# APM32F446 register map
File version: 1.0
CPU: CM4 r0p1, little endian, MPU, FPU, 4 interrupt priority bits
Registers are 32-bit, read-write, reset 0x0 unless marked. A register's access mark holds for its fields unless they carry their own. Offsets are from the block's base; [hi:lo] are bit positions; {n}, {i} and the like mark numbered series.

## LPSPI0 — The LPSPI Memory Map/Register Definition can be found here.
Base 0x4002C000
Same registers: LPSPI1 0x4002D000, LPSPI2 0x4002E000
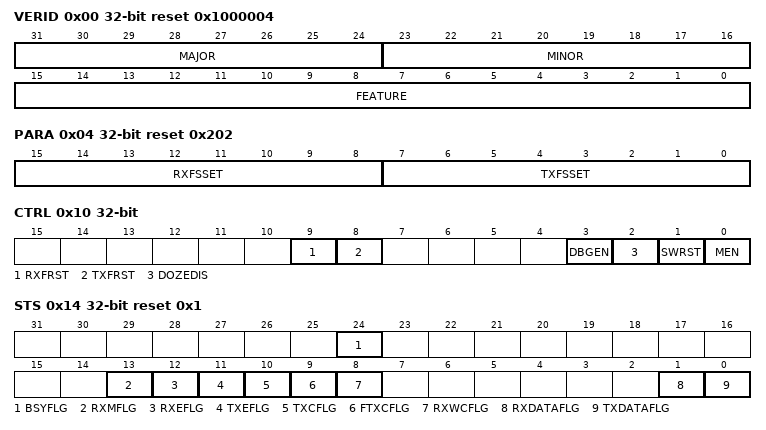
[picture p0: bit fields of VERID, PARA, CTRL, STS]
0x00 VERID ro reset 0x1000004 — Version ID Register
  [31:24] MAJOR — Major Version Number
  [23:16] MINOR — Minor Version Number
  [15:0] FEATURE — Feature Number
    4=Standard feature set supporting 32-bit shift register
0x04 PARA ro reset 0x202 — Parameter Register
  [15:8] RXFSSET — Receive FIFO Size Set
  [7:0] TXFSSET — Transmit FIFO Size Set
0x10 CTRL — Control Register
  [9] RXFRST wo — Receive FIFO Reset
    0=No effect; 1=Receive FIFO is reset
  [8] TXFRST wo — Transmit FIFO Reset
    0=No effect; 1=Transmit FIFO is reset
  [3] DBGEN — Enable LPSPI in Debug Mode
    0=Module is disabled in debug mode; 1=Module is enabled in debug mode
  [2] DOZEDIS — Disable LPSPI in Doze Mode
    0=Module is enabled in Doze mode; 1=Module is disabled in Doze mode
  [1] SWRST — Software Reset
    0=Master logic is not reset; 1=Master logic is reset
  [0] MEN — Module Enable
    0=Module is disabled; 1=Module is enabled
0x14 STS reset 0x1 — Status Register
  [24] BSYFLG ro — LPSPI Busy Flag
    0=LPSPI is idle; 1=LPSPI is busy
  [13] RXMFLG — Receive Data Match Flag
    0=Have not received matching data; 1=Have received matching data
  [12] RXEFLG — Receive Error Flag
    0=Receive FIFO has not overflowed; 1=Receive FIFO has overflowed
  [11] TXEFLG — Transmit Error Flag
    0=Transmit FIFO underrun has not occurred; 1=Transmit FIFO underrun has occurred
  [10] TXCFLG — Transfer Complete Flag
    0=All transfers have not completed; 1=All transfers have completed
  [9] FTXCFLG — Frame Complete Flag
    0=Frame transfer has not completed; 1=Frame transfer has completed
  [8] RXWCFLG — Received Word Complete Flag
    0=Transfer word not completed; 1=Transfer word completed
  [1] RXDATAFLG ro — Receive Data Flag
    0=Receive Data is not ready; 1=Receive data is ready
  [0] TXDATAFLG ro — Transmit Data Flag
    0=Transmit data not requested; 1=Transmit data is requested
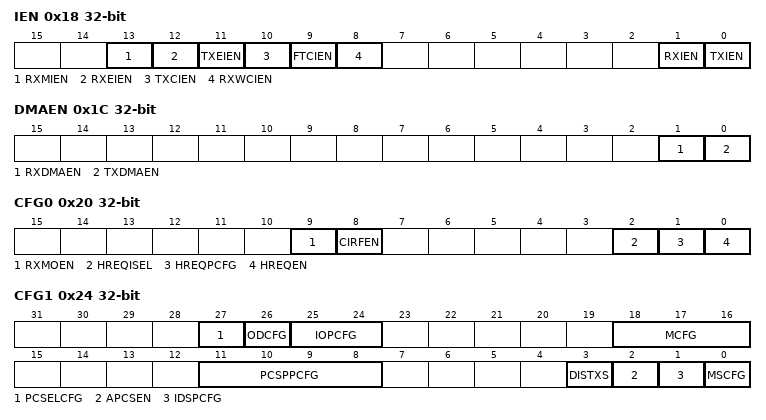
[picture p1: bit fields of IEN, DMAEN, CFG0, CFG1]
0x18 IEN — Interrupt Enable Register
  [all] fields
    0=Interrupt disabled; 1=Interrupt enabled
  [13] RXMIEN — Receive Data Match Interrupt Enable
  [12] RXEIEN — Receive Error Interrupt Enable
  [11] TXEIEN — Transmit Error Interrupt Enable
  [10] TXCIEN — Transfer Complete Interrupt Enable
  [9] FTCIEN — Frame Transfer Complete Interrupt Enable
  [8] RXWCIEN — Receive Word Complete Interrupt Enable
  [1] RXIEN — Receive Data Interrupt Enable
  [0] TXIEN — Transmit Data Interrupt Enable
0x1C DMAEN — DMA Enable Register
  [1] RXDMAEN — Receive Data DMA Enable
    0=DMA request disabled; 1=DMA request enabled
  [0] TXDMAEN — Transmit Data DMA Enable
    0=DMA request disabled; 1=DMA request enabled
0x20 CFG0 — Configure Register 0
  [9] RXMOEN — Receive Data Match Only Enable
    0=Received data is stored in the receive FIFO as normal; 1=Received data is discarded unless the DMF is set
  [8] CIRFEN — Circular FIFO Enable
    0=Circular FIFO is disabled; 1=Circular FIFO is enabled
  [2] HREQISEL — Master Request Input Select
    0=Host request input is pin LPSPI_HREQ; 1=Host request input is input trigger
  [1] HREQPCFG — Master Request Polarity Configure
    0=Active low; 1=Active high
  [0] HREQEN — Master Request Enable
    0=Host request is disabled; 1=Host request is enabled
0x24 CFG1 — Configure Register 1
  [27] PCSELCFG — Peripheral Chip Select Configure
    0=PCS[3:2] are enabled; 1=PCS[3:2] are disabled
  [26] ODCFG — Output Data Configure
    0=Output data retains last value when chip select is negated; 1=Output data is tristated when chip select is negated
  [25:24] IOPCFG — Input/Output Pin Configure
    0=SIN is used for input data and SOUT for output data; 1=SIN is used for both input and output data; 2=SOUT is used for both input and output data; 3=SOUT is used for input data and SIN for output data
  [18:16] MCFG — Match Configure
    0=Match is disabled; 2=010b - Match is enabled, if 1st data word equals COMPVAL0 OR COMPVAL1, i.e., (1st data word = COMPVAL0 + COMPVAL1); 3=011b - Match is enabled, if any data word equals COMPVAL0 OR COMPVAL1, i.e., (any data word = COMPVAL0 + COMPVAL1); 4=100b - Match is enabled, if 1st data word equals COMPVAL0 AND 2nd data word equals COMPVAL1, i.e., [(1st data word = COMPVAL0) * (2nd data word = COMPVAL1)]; 5=101b - Match is enabled, if any data word equals COMPVAL0 AND the next data word equals COMPVAL1, i.e., [(any data word = COMPVAL0) * (next data word = COMPVAL1)]; 6=110b - Match is enabled, if (1st data word AND COMPVAL1) equals (COMPVAL0 AND COMPVAL1), i.e., [(1st data word * COMPVAL1) = (COMPVAL0 * COMPVAL1)]; 7=111b - Match is enabled, if (any data word AND COMPVAL1) equals (COMPVAL0 AND COMPVAL1), i.e., [(any data word * COMPVAL1) = (COMPVAL0 * COMPVAL1)]
  [11:8] PCSPPCFG — Peripheral Chip Select Pin Polarity Configure
    0=The PCSx is active low; 1=The PCSx is active high
  [3] DISTXS — Disable Transmit Stop
    0=Transfers will stall when transmit FIFO is empty or receive FIFO is full; 1=Transfers will not stall, allowing transmit FIFO underrun or receive FIFO overrun to occur
  [2] APCSEN — Automatic PCS Enable
    0=Automatic PCS generation disabled; 1=Automatic PCS generation enabled
  [1] IDSPCFG — Input Data Sample Point Configure
    0=Input data sampled on SCK edge; 1=Input data sampled on delayed SCK edge
  [0] MSCFG — Master/Slave Mode Configure
    0=Slave mode; 1=Master mode
0x30 DATAM0 — Data Match Register 0
  [31:0] COMPVAL0 — Match 0 Value
0x34 DATAM1 — Data Match Register 1
  [31:0] COMPVAL1 — Compare Match 1 Value
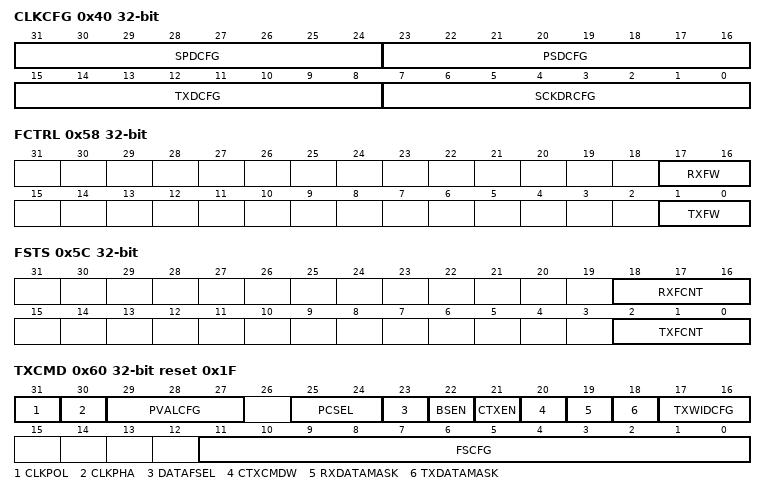
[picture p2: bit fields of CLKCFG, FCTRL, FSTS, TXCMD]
0x40 CLKCFG — Clock Configure Register
  [31:24] SPDCFG — SCK-to-PCS Delay Configure
  [23:16] PSDCFG — PCS-to-SCK Delay Configure
  [15:8] TXDCFG — Transfers Delay Configure
  [7:0] SCKDRCFG — SCK Divide Ratio Configure
0x58 FCTRL — FIFO Control Register
  [17:16] RXFW — Receive FIFO Watermark
  [1:0] TXFW — Transmit FIFO Watermark
0x5C FSTS ro — FIFO Status Register
  [18:16] RXFCNT — Receive FIFO Count
  [2:0] TXFCNT — Transmit FIFO Count
0x60 TXCMD reset 0x1F — Transmit Command Register
  [31] CLKPOL — Clock Polarity Configure
    0=The inactive state value of SCK is low; 1=The inactive state value of SCK is high
  [30] CLKPHA — Clock Phase Configure
    0=Data is captured on the leading edge of SCK and changed on the following edge; 1=Data is changed on the leading edge of SCK and captured on the following edge
  [29:27] PVALCFG — Prescaler Value Configure
    0=Divide by 1; 1=Divide by 2; 2=Divide by 4; 3=Divide by 8; 4=Divide by 16; 5=Divide by 32; 6=Divide by 64; 7=Divide by 128
  [25:24] PCSEL — Peripheral Chip Select
    {v}=Transfer using LPSPI_PCS[{v}] (v=0..3)
  [23] DATAFSEL — Data First Select
    0=Data is transferred MSB first; 1=Data is transferred LSB first
  [22] BSEN — Byte Swap Enable
    0=Byte swap disabled; 1=Byte swap enabled
  [21] CTXEN — Continuous Transfer Enable
    0=Continuous transfer disabled; 1=Continuous transfer enabled
  [20] CTXCMDW — Continuing Transfer Command Word
    0=Command word for start of new transfer; 1=Command word for continuing transfer
  [19] RXDATAMASK — Receive Data Mask
    0=Normal transfer; 1=Receive data is masked
  [18] TXDATAMASK — Transmit Data Mask
    0=Normal transfer; 1=Mask transmit data
  [17:16] TXWIDCFG — Transfer Width Configure
    0=Single bit transfer; 1=Two bit transfer; 2=Four bit transfer
  [11:0] FSCFG — Frame Size Configure
0x64 TXDATA wo — Transmit Data Register
  [31:0] TXDATA — Transmit Data
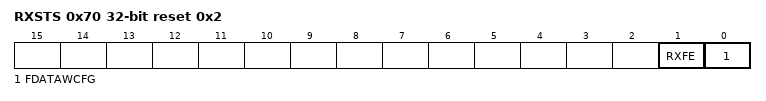
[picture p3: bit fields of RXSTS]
0x70 RXSTS ro reset 0x2 — Receive Status Register
  [1] RXFE — Receive FIFO Empty
    0=RX FIFO is not empty; 1=RX FIFO is empty
  [0] FDATAWCFG — First Data Word Configure
    0=Subsequent data word received after LPSPI_PCS assertion; 1=First data word received after LPSPI_PCS assertion
0x74 RXDATA ro — Receive Data Register
  [31:0] RXDATA — Receive Data
